AUTOSAR XML (schema 314)
package /ComponentType
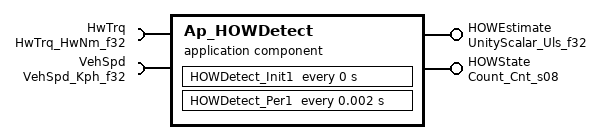
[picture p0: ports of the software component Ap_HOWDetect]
  application software component type Ap_HOWDetect
    provide port HOWEstimate: unqueued-sender-com-spec{data-element=Uls_f32, can-invalidate=false, init-value=D_ZERO_ULS_F32}, provided-interface=UnityScalar_Uls_f32
    provide port HOWState: unqueued-sender-com-spec{data-element=Cnt_s08, can-invalidate=false, init-value=D_ZERO_CNT_S8}, provided-interface=Count_Cnt_s08
    require port HwTrq: unqueued-receiver-com-spec{data-element=HwNm_f32, init-value=D_ZERO_ULS_F32}, required-interface=HwTrq_HwNm_f32
    require port VehSpd: unqueued-receiver-com-spec{data-element=Kph_f32, init-value=D_ZERO_ULS_F32}, required-interface=VehSpd_Kph_f32
  internal behavior Ap_HOWDetect_InternalBehavior: component=Ap_HOWDetect
    timing event HOWDetect_Init1_InitEvent: start-on-event=HOWDetect_Init1, period=0
    timing event TMT_HOWDetect_Per1: start-on-event=HOWDetect_Per1, period=0.002
    port-api-options:
      enable-take-address=false, indirect-api=false, port=HOWEstimate
      enable-take-address=false, indirect-api=false, port=HOWState
      enable-take-address=false, indirect-api=false, port=HwTrq
      enable-take-address=false, indirect-api=false, port=VehSpd
    runnable HOWDetect_Init1
    runnable HOWDetect_Per1
      data read access READ_HwTrq_HwNm_f32: data-element=HwTrq.HwNm_f32
      data read access READ_VehSpd_Kph_f32: data-element=VehSpd.Kph_f32
      data write access WRITE_HOWEstimate_Uls_f32: data-element=HOWEstimate.Uls_f32
      data write access WRITE_HOWState_Cnt_s08: data-element=HOWState.Cnt_s08
  swc implementation Ap_HOWDetect_Implementation: behavior=Ap_HOWDetect_InternalBehavior
    code-descriptors:
      code Code: type=SRC
